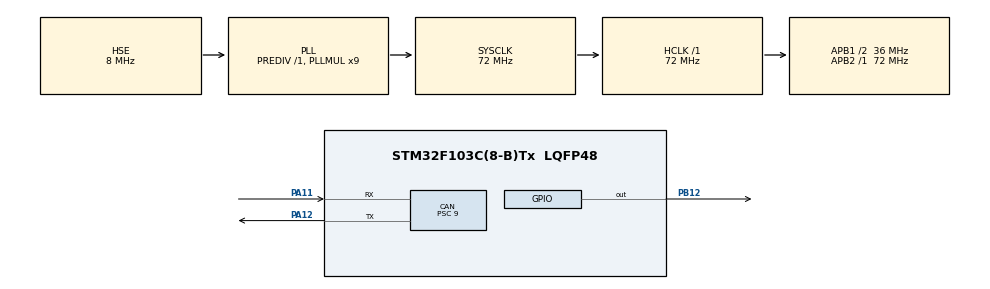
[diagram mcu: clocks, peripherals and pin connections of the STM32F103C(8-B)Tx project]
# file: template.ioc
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CAN.ABOM=ENABLE
CAN.BS1=CAN_BS1_6TQ
CAN.CalculateTimeBit=2000
CAN.CalculateTimeQuantum=250.0
CAN.Mode=CAN_MODE_NORMAL
CAN.NART=ENABLE
CAN.Prescaler=9
CAN.SJW=CAN_SJW_1TQ
CAN.TXFP=ENABLE
Mcu.Family=STM32F1
Mcu.Name=STM32F103C(8-B)Tx
Mcu.Package=LQFP48
NVIC.CAN1_RX1_IRQn=true\:0\:0\:false\:false\:true\:true
NVIC.CAN1_SCE_IRQn=true\:0\:0\:false\:false\:true\:true
NVIC.PriorityGroup=NVIC_PRIORITYGROUP_4
NVIC.USB_HP_CAN1_TX_IRQn=true\:0\:0\:false\:false\:true\:true
NVIC.USB_LP_CAN1_RX0_IRQn=true\:0\:0\:false\:false\:true\:true
PA11.GPIO_PuPd=GPIO_NOPULL
PA11.Mode=Master
PA11.Signal=CAN_RX
PA12.Mode=Master
PA12.Signal=CAN_TX
PA13.Mode=Serial_Wire
PA13.Signal=SYS_JTMS-SWDIO
PA14.Mode=Serial_Wire
PA14.Signal=SYS_JTCK-SWCLK
PB12.Signal=GPIO_Output
PC14-OSC32_IN.Mode=LSE-External-Oscillator
PC14-OSC32_IN.Signal=RCC_OSC32_IN
PC15-OSC32_OUT.Mode=LSE-External-Oscillator
PC15-OSC32_OUT.Signal=RCC_OSC32_OUT
PD0-OSC_IN.Mode=HSE-External-Oscillator
PD0-OSC_IN.Signal=RCC_OSC_IN
PD1-OSC_OUT.Mode=HSE-External-Oscillator
PD1-OSC_OUT.Signal=RCC_OSC_OUT
ProjectManager.HeapSize=0x200
ProjectManager.StackSize=0x400
ProjectManager.TargetToolchain=Makefile
RCC.AHBFreq_Value=72000000
RCC.APB1CLKDivider=RCC_HCLK_DIV2
RCC.APB1Freq_Value=36000000
RCC.APB1TimFreq_Value=72000000
RCC.APB2Freq_Value=72000000
RCC.APB2TimFreq_Value=72000000
RCC.HCLKFreq_Value=72000000
RCC.PLLMUL=RCC_PLL_MUL9
RCC.PLLSourceVirtual=RCC_PLLSOURCE_HSE
RCC.SYSCLKFreq_VALUE=72000000
RCC.SYSCLKSource=RCC_SYSCLKSOURCE_PLLCLK
RCC.USBFreq_Value=72000000
VP_CRC_VS_CRC.Mode=CRC_Activate
board=custom

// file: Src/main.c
/* USER CODE BEGIN Header */
/**
 ******************************************************************************
 * @file           : main.c
 * @brief          : Main program body
 ******************************************************************************
 ** This notice applies to any and all portions of this file
 * that are not between comment pairs USER CODE BEGIN and
 * USER CODE END. Other portions of this file, whether
 * inserted by the user or by software development tools
 * are owned by their respective copyright owners.
 *
 * COPYRIGHT(c) 2019 STMicroelectronics
 *
 * Redistribution and use in source and binary forms, with or without
 *modification, are permitted provided that the following conditions are met:
 *   1. Redistributions of source code must retain the above copyright notice,
 *      this list of conditions and the following disclaimer.
 *   2. Redistributions in binary form must reproduce the above copyright
 *notice, this list of conditions and the following disclaimer in the
 *documentation and/or other materials provided with the distribution.
 *   3. Neither the name of STMicroelectronics nor the names of its contributors
 *      may be used to endorse or promote products derived from this software
 *      without specific prior written permission.
 *
 * THIS SOFTWARE IS PROVIDED BY THE COPYRIGHT HOLDERS AND CONTRIBUTORS "AS IS"
 * AND ANY EXPRESS OR IMPLIED WARRANTIES, INCLUDING, BUT NOT LIMITED TO, THE
 * IMPLIED WARRANTIES OF MERCHANTABILITY AND FITNESS FOR A PARTICULAR PURPOSE
 *ARE DISCLAIMED. IN NO EVENT SHALL THE COPYRIGHT HOLDER OR CONTRIBUTORS BE
 *LIABLE FOR ANY DIRECT, INDIRECT, INCIDENTAL, SPECIAL, EXEMPLARY, OR
 *CONSEQUENTIAL DAMAGES (INCLUDING, BUT NOT LIMITED TO, PROCUREMENT OF
 *SUBSTITUTE GOODS OR SERVICES; LOSS OF USE, DATA, OR PROFITS; OR BUSINESS
 *INTERRUPTION) HOWEVER CAUSED AND ON ANY THEORY OF LIABILITY, WHETHER IN
 *CONTRACT, STRICT LIABILITY, OR TORT (INCLUDING NEGLIGENCE OR OTHERWISE)
 *ARISING IN ANY WAY OUT OF THE USE OF THIS SOFTWARE, EVEN IF ADVISED OF THE
 *POSSIBILITY OF SUCH DAMAGE.
 *
 ******************************************************************************
 */
/* USER CODE END Header */

#include "main.h"

/* USER CODE BEGIN Includes */
#include "rubi.h"

RUBI_UNIVERSAL_BOARD("BlackpillTemplate", "1.0", "rubi_generic",
                     "Example project for blackpill.", 10);

RUBI_REGISTER_FIELD(red_led, RUBI_READONLY, bool_t)
RUBI_REGISTER_FIELD(time, RUBI_WRITEONLY, int32_t)
RUBI_REGISTER_FIELD(time_str, RUBI_WRITEONLY, shortstring)
RUBI_REGISTER_FIELD(time_float, RUBI_WRITEONLY, float)

RUBI_REGISTER_FIELD(readwrite_test1, RUBI_READWRITE, int32_t)
RUBI_REGISTER_FIELD(readwrite_test2, RUBI_READWRITE, bool_t, b1, b2)

RUBI_REGISTER_FIELD(i32, RUBI_WRITEONLY, int32_t)
RUBI_REGISTER_FIELD(i16, RUBI_WRITEONLY, int16_t)
RUBI_REGISTER_FIELD(i8, RUBI_WRITEONLY, int8_t)
RUBI_REGISTER_FIELD(u32, RUBI_WRITEONLY, uint32_t)
RUBI_REGISTER_FIELD(u16, RUBI_WRITEONLY, uint16_t)
RUBI_REGISTER_FIELD(u8, RUBI_WRITEONLY, uint8_t)

RUBI_REGISTER_FIELD(in_i32, RUBI_READONLY, int32_t)
RUBI_REGISTER_FIELD(in_i16, RUBI_READONLY, int16_t)
RUBI_REGISTER_FIELD(in_i8, RUBI_READONLY, int8_t)
RUBI_REGISTER_FIELD(in_u32, RUBI_READONLY, uint32_t)
RUBI_REGISTER_FIELD(in_u16, RUBI_READONLY, uint16_t)
RUBI_REGISTER_FIELD(in_u8, RUBI_READONLY, uint8_t)

RUBI_END()
/* USER CODE END Includes */

CAN_HandleTypeDef hcan;

CRC_HandleTypeDef hcrc;

/* USER CODE BEGIN PV */
/* Private variables ---------------------------------------------------------*/

/* USER CODE END PV */

void SystemClock_Config(void);
static void MX_GPIO_Init(void);
static void MX_CAN_Init(void);
static void MX_CRC_Init(void);
/* USER CODE BEGIN PFP */
/* Private function prototypes -----------------------------------------------*/

/* USER CODE END PFP */

/* USER CODE BEGIN 0 */

// THOSE CALLBACKS ARE ASYNCHRONOUS!

void rubi_callback_operational() {}

void rubi_callback_lost() {}

void rubi_callback_error() {}

void rubi_callback_prepare_sleep() {}

void rubi_callback_wakeup() {}

void rubi_callback_shutdown() {}

void HAL_SYSTICK_Callback()
{
    time += 1;
    sprintf(time_str, "%ld", time);
    time_float = (float)time / 1000.0;

    i32 = in_i32;
    i16 = in_i16;
    i8 = in_i8;
    u32 = in_u32;
    u16 = in_u16;
    u8 = in_u8;

    if (red_led)
        HAL_GPIO_WritePin(GPIOB, GPIO_PIN_12, GPIO_PIN_RESET);
    else
        HAL_GPIO_WritePin(GPIOB, GPIO_PIN_12, GPIO_PIN_SET);
}

/* USER CODE END 0 */

int main(void)
{

    /* MCU
     * Configuration--------------------------------------------------------*/

    /* Reset of all peripherals, Initializes the Flash interface and the
     * Systick. */
    HAL_Init();

    /* Configure the system clock */
    SystemClock_Config();

    /* Initialize all configured peripherals */
    MX_GPIO_Init();
    MX_CAN_Init();
    MX_CRC_Init();
    /* USER CODE BEGIN 2 */
    HAL_CRC_Init(&hcrc);

    rubi_singleboard_init();
    rubi_wakeup(); // make board wake by default

    /* USER CODE END 2 */

    /* Infinite loop */
    /* USER CODE BEGIN WHILE */

    while (1)
    {
        readwrite_test1 += 1;
        readwrite_test2.b1 = !readwrite_test2.b1;
        readwrite_test2.b2 = true;

        HAL_Delay(1000);

        /* USER CODE END WHILE */

    }
}

void SystemClock_Config(void)
{
    RCC_OscInitTypeDef RCC_OscInitStruct = {0};
    RCC_ClkInitTypeDef RCC_ClkInitStruct = {0};

    /**Initializes the CPU, AHB and APB busses clocks
     */
    RCC_OscInitStruct.OscillatorType = RCC_OSCILLATORTYPE_HSE;
    RCC_OscInitStruct.HSEState = RCC_HSE_ON;
    RCC_OscInitStruct.HSEPredivValue = RCC_HSE_PREDIV_DIV1;
    RCC_OscInitStruct.HSIState = RCC_HSI_ON;
    RCC_OscInitStruct.PLL.PLLState = RCC_PLL_ON;
    RCC_OscInitStruct.PLL.PLLSource = RCC_PLLSOURCE_HSE;
    RCC_OscInitStruct.PLL.PLLMUL = RCC_PLL_MUL9;
    if (HAL_RCC_OscConfig(&RCC_OscInitStruct) != HAL_OK)
    {
        Error_Handler();
    }
    /**Initializes the CPU, AHB and APB busses clocks
     */
    RCC_ClkInitStruct.ClockType = RCC_CLOCKTYPE_HCLK | RCC_CLOCKTYPE_SYSCLK |
                                  RCC_CLOCKTYPE_PCLK1 | RCC_CLOCKTYPE_PCLK2;
    RCC_ClkInitStruct.SYSCLKSource = RCC_SYSCLKSOURCE_PLLCLK;
    RCC_ClkInitStruct.AHBCLKDivider = RCC_SYSCLK_DIV1;
    RCC_ClkInitStruct.APB1CLKDivider = RCC_HCLK_DIV2;
    RCC_ClkInitStruct.APB2CLKDivider = RCC_HCLK_DIV1;

    if (HAL_RCC_ClockConfig(&RCC_ClkInitStruct, FLASH_LATENCY_2) != HAL_OK)
    {
        Error_Handler();
    }
}

static void MX_CAN_Init(void)
{

    hcan.Instance = CAN1;
    hcan.Init.Prescaler = 9;
    hcan.Init.Mode = CAN_MODE_NORMAL;
    hcan.Init.SyncJumpWidth = CAN_SJW_1TQ;
    hcan.Init.TimeSeg1 = CAN_BS1_6TQ;
    hcan.Init.TimeSeg2 = CAN_BS2_1TQ;
    hcan.Init.TimeTriggeredMode = DISABLE;
    hcan.Init.AutoBusOff = ENABLE;
    hcan.Init.AutoWakeUp = DISABLE;
    hcan.Init.AutoRetransmission = ENABLE;
    hcan.Init.ReceiveFifoLocked = DISABLE;
    hcan.Init.TransmitFifoPriority = ENABLE;
    if (HAL_CAN_Init(&hcan) != HAL_OK)
    {
        Error_Handler();
    }
}

static void MX_CRC_Init(void)
{

    hcrc.Instance = CRC;
    if (HAL_CRC_Init(&hcrc) != HAL_OK)
    {
        Error_Handler();
    }
}

static void MX_GPIO_Init(void)
{
    GPIO_InitTypeDef GPIO_InitStruct = {0};

    /* GPIO Ports Clock Enable */
    __HAL_RCC_GPIOC_CLK_ENABLE();
    __HAL_RCC_GPIOD_CLK_ENABLE();
    __HAL_RCC_GPIOB_CLK_ENABLE();
    __HAL_RCC_GPIOA_CLK_ENABLE();

    /*Configure GPIO pin Output Level */
    HAL_GPIO_WritePin(GPIOB, GPIO_PIN_12, GPIO_PIN_RESET);

    /*Configure GPIO pin : PB12 */
    GPIO_InitStruct.Pin = GPIO_PIN_12;
    GPIO_InitStruct.Mode = GPIO_MODE_OUTPUT_PP;
    GPIO_InitStruct.Pull = GPIO_NOPULL;
    GPIO_InitStruct.Speed = GPIO_SPEED_FREQ_LOW;
    HAL_GPIO_Init(GPIOB, &GPIO_InitStruct);
}

void Error_Handler(void)
{
    /* USER CODE BEGIN Error_Handler_Debug */
    /* User can add his own implementation to report the HAL error return state
     */
    while (1)
    {
    }
    /* USER CODE END Error_Handler_Debug */
}

#ifdef USE_FULL_ASSERT
/**
 * @brief  Reports the name of the source file and the source line number
 *         where the assert_param error has occurred.
 * @param  file: pointer to the source file name
 * @param  line: assert_param error line source number
 * @retval None
 */
void assert_failed(uint8_t *file, uint32_t line)
{
    /* USER CODE BEGIN 6 */
    /* User can add his own implementation to report the file name and line
       number, tex: printf("Wrong parameters value: file %s on line %d\r\n",
       file, line) */
    /* USER CODE END 6 */
}
#endif /* USE_FULL_ASSERT */

/************************ (C) COPYRIGHT STMicroelectronics *****END OF FILE****/
